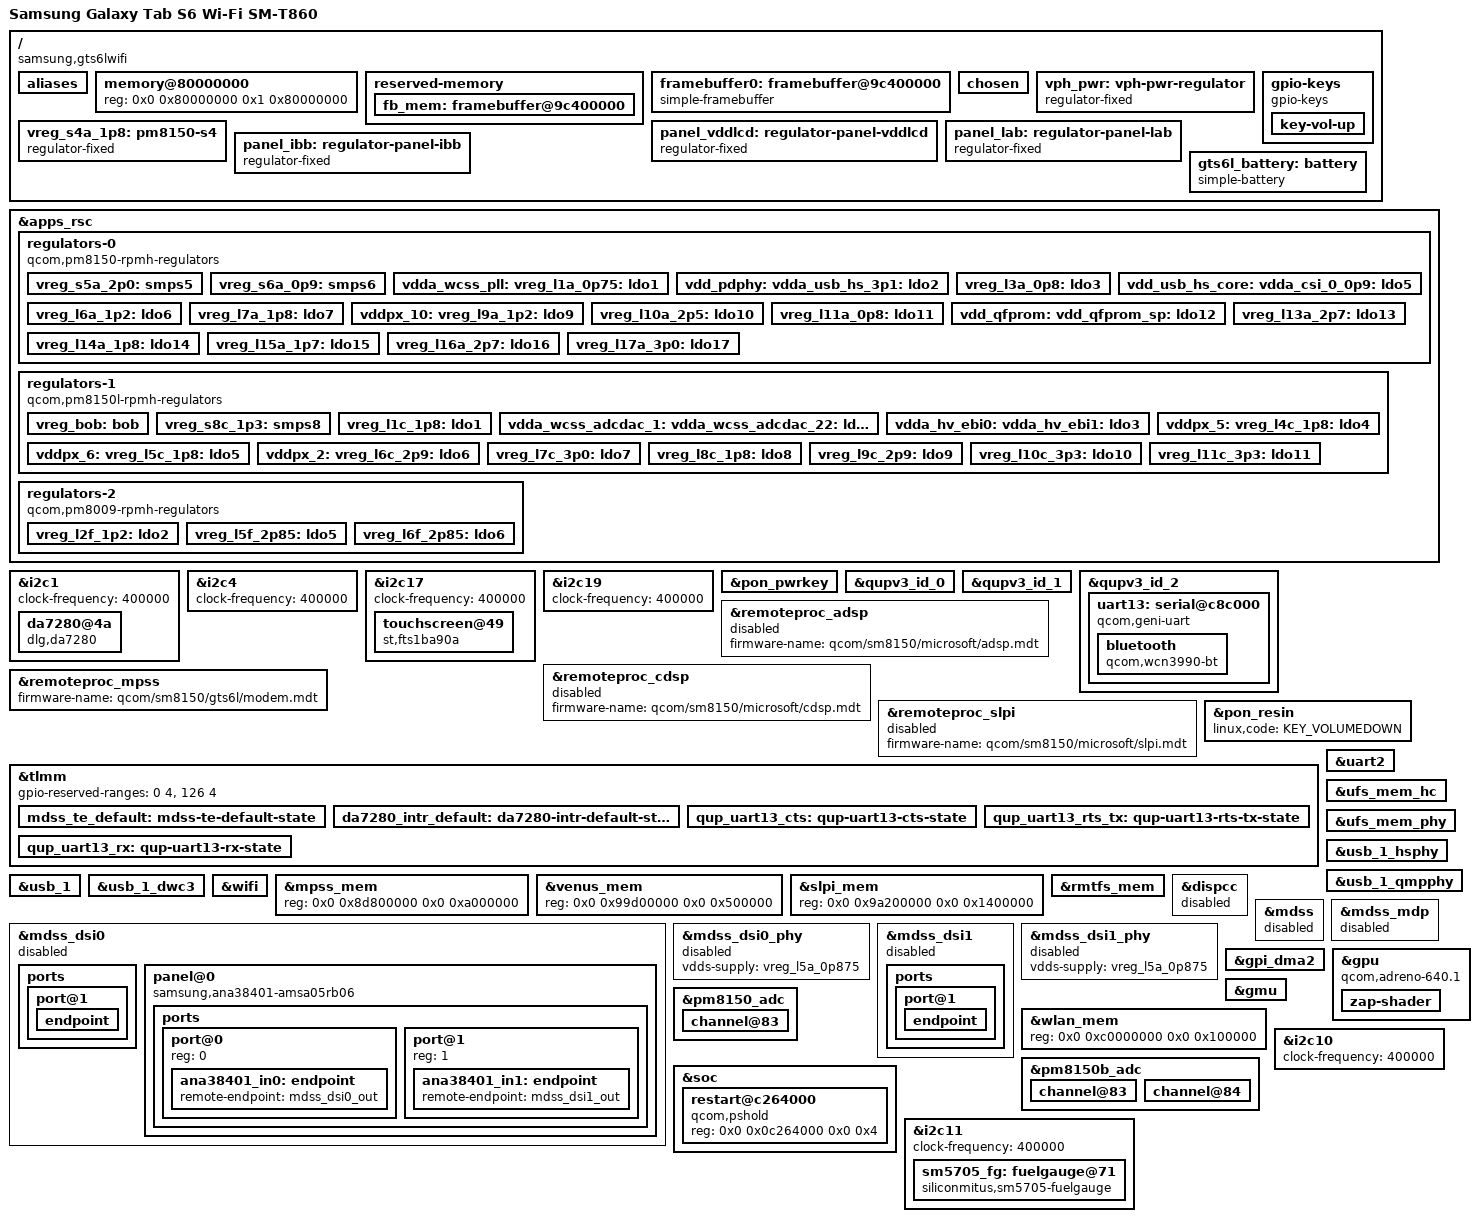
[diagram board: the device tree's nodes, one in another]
// SPDX-License-Identifier: BSD-3-Clause
/*
 * Copyright (C) 2021, Microsoft Corporation
 */

/dts-v1/;

#include <dt-bindings/regulator/qcom,rpmh-regulator.h>
#include <dt-bindings/gpio/gpio.h>
#include "sm8150.dtsi"
#include "pm8150.dtsi"
#include "pm8150b.dtsi"
#include "pm8150l.dtsi"

/ {
	model = "Samsung Galaxy Tab S6 Wi-Fi SM-T860";
	compatible = "samsung,gts6lwifi", "qcom,sm8150p", "qcom,sm8150";
	chassis-type = "tablet";

	aliases {
		serial0 = &uart2;
		/*
		 * qcom_geni_serial takes its port index from an alias, trying
		 * "serial" then "hsuart". With neither present of_alias_get_id
		 * returns -ENODEV and the probe dies with the shruggingly
		 * unhelpful "Invalid line -19". Downstream calls this same node
		 * hsuart0; serial1 is the mainline spelling and the non-console
		 * driver has its own 3-entry port array, so it does not collide
		 * with serial0 above.
		 */
		serial1 = &uart13;
	};

	memory@80000000 {
		device_type = "memory";
		reg = <0x0 0x80000000 0x1 0x80000000>;
	};

	reserved-memory {
		#address-cells = <2>;
		#size-cells = <2>;
		ranges;

		fb_mem: framebuffer@9c400000 {
			reg = <0x0 0x9c400000 0x0 0x02000000>;
			no-map;
		};
	};

	framebuffer0: framebuffer@9c400000 {
		compatible = "simple-framebuffer";
		reg = <0x0 0x9c400000 0x0 (2560 * 1600 * 4)>;
		width = <2560>;
		height = <1600>;
		stride = <(2560 * 4)>;
		format = "a8r8g8b8";
	};

	chosen {
		bootargs = "console=tty0 ignore_loglevel loglevel=8 rootwait";
	};

	vph_pwr: vph-pwr-regulator {
		compatible = "regulator-fixed";
		regulator-name = "vph_pwr";
		regulator-min-microvolt = <3700000>;
		regulator-max-microvolt = <3700000>;
	};

	/*
	 * Apparently RPMh does not provide support for PM8150 S4 because it
	 * is always-on; model it as a fixed regulator.
	 */
	vreg_s4a_1p8: pm8150-s4 {
		compatible = "regulator-fixed";
		regulator-name = "vreg_s4a_1p8";

		regulator-min-microvolt = <1800000>;
		regulator-max-microvolt = <1800000>;

		regulator-always-on;
		regulator-boot-on;

		vin-supply = <&vph_pwr>;
	};

	gpio-keys {
		compatible = "gpio-keys";

		key-vol-up {
			label = "Volume Up";
			gpios = <&pm8150_gpios 6 GPIO_ACTIVE_LOW>;
			linux,code = <KEY_VOLUMEUP>;
		};
	};
};

&apps_rsc {
	regulators-0 {
		compatible = "qcom,pm8150-rpmh-regulators";
		qcom,pmic-id = "a";

		vdd-s1-supply = <&vph_pwr>;
		vdd-s2-supply = <&vph_pwr>;
		vdd-s3-supply = <&vph_pwr>;
		vdd-s4-supply = <&vph_pwr>;
		vdd-s5-supply = <&vph_pwr>;
		vdd-s6-supply = <&vph_pwr>;
		vdd-s7-supply = <&vph_pwr>;
		vdd-s8-supply = <&vph_pwr>;
		vdd-s9-supply = <&vph_pwr>;
		vdd-s10-supply = <&vph_pwr>;

		vdd-l1-l8-l11-supply = <&vreg_s6a_0p9>;
		vdd-l2-l10-supply = <&vreg_bob>;
		vdd-l3-l4-l5-l18-supply = <&vreg_s6a_0p9>;
		vdd-l6-l9-supply = <&vreg_s8c_1p3>;
		vdd-l7-l12-l14-l15-supply = <&vreg_s5a_2p0>;
		vdd-l13-l16-l17-supply = <&vreg_bob>;

		vreg_s5a_2p0: smps5 {
			regulator-min-microvolt = <1904000>;
			regulator-max-microvolt = <2000000>;
		};

		vreg_s6a_0p9: smps6 {
			regulator-min-microvolt = <920000>;
			regulator-max-microvolt = <1128000>;
		};

		vdda_wcss_pll:
		vreg_l1a_0p75: ldo1 {
			regulator-min-microvolt = <752000>;
			regulator-max-microvolt = <752000>;
			regulator-initial-mode = <RPMH_REGULATOR_MODE_HPM>;
		};

		vdd_pdphy:
		vdda_usb_hs_3p1:
		vreg_l2a_3p1: ldo2 {
			regulator-min-microvolt = <3072000>;
			regulator-max-microvolt = <3072000>;
			regulator-initial-mode = <RPMH_REGULATOR_MODE_HPM>;
		};

		vreg_l3a_0p8: ldo3 {
			regulator-min-microvolt = <480000>;
			regulator-max-microvolt = <932000>;
			regulator-initial-mode = <RPMH_REGULATOR_MODE_HPM>;
		};

		vdd_usb_hs_core:
		vdda_csi_0_0p9:
		vdda_csi_1_0p9:
		vdda_csi_2_0p9:
		vdda_csi_3_0p9:
		vdda_dsi_0_0p9:
		vdda_dsi_1_0p9:
		vdda_dsi_0_pll_0p9:
		vdda_dsi_1_pll_0p9:
		vdda_pcie_1ln_core:
		vdda_pcie_2ln_core:
		vdda_pll_hv_cc_ebi01:
		vdda_pll_hv_cc_ebi23:
		vdda_qrefs_0p875_5:
		vdda_sp_sensor:
		vdda_ufs_2ln_core_1:
		vdda_ufs_2ln_core_2:
		vdda_usb_ss_dp_core_1:
		vdda_usb_ss_dp_core_2:
		vdda_qlink_lv:
		vdda_qlink_lv_ck:
		vreg_l5a_0p875: ldo5 {
			regulator-min-microvolt = <880000>;
			regulator-max-microvolt = <880000>;
			regulator-initial-mode = <RPMH_REGULATOR_MODE_HPM>;
		};

		vreg_l6a_1p2: ldo6 {
			regulator-min-microvolt = <1200000>;
			regulator-max-microvolt = <1200000>;
			regulator-initial-mode = <RPMH_REGULATOR_MODE_HPM>;
		};

		vreg_l7a_1p8: ldo7 {
			regulator-min-microvolt = <1800000>;
			regulator-max-microvolt = <1800000>;
			regulator-initial-mode = <RPMH_REGULATOR_MODE_HPM>;
		};

		vddpx_10:
		vreg_l9a_1p2: ldo9 {
			regulator-min-microvolt = <1200000>;
			regulator-max-microvolt = <1200000>;
			regulator-initial-mode = <RPMH_REGULATOR_MODE_HPM>;
		};

		vreg_l10a_2p5: ldo10 {
			regulator-min-microvolt = <2504000>;
			regulator-max-microvolt = <2960000>;
			regulator-initial-mode = <RPMH_REGULATOR_MODE_HPM>;
		};

		vreg_l11a_0p8: ldo11 {
			regulator-min-microvolt = <800000>;
			regulator-max-microvolt = <800000>;
			regulator-initial-mode = <RPMH_REGULATOR_MODE_HPM>;
		};

		vdd_qfprom:
		vdd_qfprom_sp:
		vdda_apc_cs_1p8:
		vdda_gfx_cs_1p8:
		vdda_usb_hs_1p8:
		vdda_qrefs_vref_1p8:
		vddpx_10_a:
		vreg_l12a_1p8: ldo12 {
			regulator-min-microvolt = <1800000>;
			regulator-max-microvolt = <1800000>;
			regulator-initial-mode = <RPMH_REGULATOR_MODE_HPM>;
		};

		vreg_l13a_2p7: ldo13 {
			regulator-min-microvolt = <2704000>;
			regulator-max-microvolt = <2704000>;
			regulator-initial-mode = <RPMH_REGULATOR_MODE_HPM>;
		};

		vreg_l14a_1p8: ldo14 {
			regulator-min-microvolt = <1800000>;
			regulator-max-microvolt = <1880000>;
			regulator-always-on;
			regulator-boot-on;
			regulator-initial-mode = <RPMH_REGULATOR_MODE_HPM>;
		};

		vreg_l15a_1p7: ldo15 {
			regulator-min-microvolt = <1704000>;
			regulator-max-microvolt = <1704000>;
			regulator-initial-mode = <RPMH_REGULATOR_MODE_HPM>;
		};

		vreg_l16a_2p7: ldo16 {
			regulator-min-microvolt = <2704000>;
			regulator-max-microvolt = <2960000>;
			regulator-initial-mode = <RPMH_REGULATOR_MODE_HPM>;
		};

		vreg_l17a_3p0: ldo17 {
			regulator-min-microvolt = <2856000>;
			regulator-max-microvolt = <3008000>;
			regulator-always-on;
			regulator-boot-on;
			regulator-initial-mode = <RPMH_REGULATOR_MODE_HPM>;
		};
	};

	regulators-1 {
		compatible = "qcom,pm8150l-rpmh-regulators";
		qcom,pmic-id = "c";

		vdd-s1-supply = <&vph_pwr>;
		vdd-s2-supply = <&vph_pwr>;
		vdd-s3-supply = <&vph_pwr>;
		vdd-s4-supply = <&vph_pwr>;
		vdd-s5-supply = <&vph_pwr>;
		vdd-s6-supply = <&vph_pwr>;
		vdd-s7-supply = <&vph_pwr>;
		vdd-s8-supply = <&vph_pwr>;

		vdd-l1-l8-supply = <&vreg_s4a_1p8>;
		vdd-l2-l3-supply = <&vreg_s8c_1p3>;
		vdd-l4-l5-l6-supply = <&vreg_bob>;
		vdd-l7-l11-supply = <&vreg_bob>;
		vdd-l9-l10-supply = <&vreg_bob>;

		vdd-bob-supply = <&vph_pwr>;
		vdd-flash-supply = <&vreg_bob>;
		vdd-rgb-supply = <&vreg_bob>;

		vreg_bob: bob {
			regulator-min-microvolt = <3008000>;
			regulator-max-microvolt = <4000000>;
			regulator-initial-mode = <RPMH_REGULATOR_MODE_AUTO>;
			regulator-allow-bypass;
		};

		vreg_s8c_1p3: smps8 {
			regulator-min-microvolt = <1352000>;
			regulator-max-microvolt = <1352000>;
		};

		vreg_l1c_1p8: ldo1 {
			regulator-min-microvolt = <1800000>;
			regulator-max-microvolt = <1800000>;
			regulator-initial-mode = <RPMH_REGULATOR_MODE_HPM>;
		};

		vdda_wcss_adcdac_1:
		vdda_wcss_adcdac_22:
		vreg_l2c_1p3: ldo2 {
			regulator-min-microvolt = <1304000>;
			regulator-max-microvolt = <1304000>;
			regulator-initial-mode = <RPMH_REGULATOR_MODE_HPM>;
			regulator-always-on;
			regulator-boot-on;
		};

		vdda_hv_ebi0:
		vdda_hv_ebi1:
		vdda_hv_ebi2:
		vdda_hv_ebi3:
		vdda_hv_refgen0:
		vdda_qlink_hv_ck:
		vreg_l3c_1p2: ldo3 {
			regulator-min-microvolt = <1200000>;
			regulator-max-microvolt = <1200000>;
			regulator-initial-mode = <RPMH_REGULATOR_MODE_HPM>;
		};

		vddpx_5:
		vreg_l4c_1p8: ldo4 {
			regulator-min-microvolt = <1704000>;
			regulator-max-microvolt = <2928000>;
			regulator-initial-mode = <RPMH_REGULATOR_MODE_HPM>;
		};

		vddpx_6:
		vreg_l5c_1p8: ldo5 {
			regulator-min-microvolt = <1704000>;
			regulator-max-microvolt = <2928000>;
			regulator-initial-mode = <RPMH_REGULATOR_MODE_HPM>;
		};

		vddpx_2:
		vreg_l6c_2p9: ldo6 {
			regulator-min-microvolt = <1800000>;
			regulator-max-microvolt = <2960000>;
			regulator-initial-mode = <RPMH_REGULATOR_MODE_HPM>;
		};

		vreg_l7c_3p0: ldo7 {
			regulator-min-microvolt = <2856000>;
			regulator-max-microvolt = <3104000>;
			regulator-initial-mode = <RPMH_REGULATOR_MODE_HPM>;
		};

		vreg_l8c_1p8: ldo8 {
			regulator-min-microvolt = <1800000>;
			regulator-max-microvolt = <1800000>;
			regulator-initial-mode = <RPMH_REGULATOR_MODE_HPM>;
		};

		vreg_l9c_2p9: ldo9 {
			regulator-min-microvolt = <2704000>;
			regulator-max-microvolt = <2960000>;
			regulator-initial-mode = <RPMH_REGULATOR_MODE_HPM>;
		};

		vreg_l10c_3p3: ldo10 {
			regulator-min-microvolt = <3000000>;
			regulator-max-microvolt = <3312000>;
			regulator-initial-mode = <RPMH_REGULATOR_MODE_HPM>;
		};

		vreg_l11c_3p3: ldo11 {
			regulator-min-microvolt = <3312000>;
			regulator-max-microvolt = <3312000>;
			regulator-initial-mode = <RPMH_REGULATOR_MODE_HPM>;
			regulator-always-on;
			regulator-boot-on;
		};
	};

	regulators-2 {
		compatible = "qcom,pm8009-rpmh-regulators";
		qcom,pmic-id = "f";

		vdd-s1-supply = <&vph_pwr>;
		vdd-s2-supply = <&vreg_bob>;

		vdd-l2-supply = <&vreg_s8c_1p3>;
		vdd-l5-l6-supply = <&vreg_bob>;

		vreg_l2f_1p2: ldo2 {
			regulator-min-microvolt = <1200000>;
			regulator-max-microvolt = <1200000>;
			regulator-initial-mode = <RPMH_REGULATOR_MODE_HPM>;
		};

		vreg_l5f_2p85: ldo5 {
			regulator-min-microvolt = <2800000>;
			regulator-max-microvolt = <2800000>;
			regulator-initial-mode = <RPMH_REGULATOR_MODE_HPM>;
		};

		vreg_l6f_2p85: ldo6 {
			regulator-initial-mode = <RPMH_REGULATOR_MODE_HPM>;
			regulator-min-microvolt = <2856000>;
			regulator-max-microvolt = <2856000>;
		};
	};
};

&i2c1 {
	status = "okay";
	clock-frequency = <400000>;


	da7280@4a {
		compatible = "dlg,da7280";
		reg = <0x4a>;
		interrupts-extended = <&tlmm 42 IRQ_TYPE_LEVEL_LOW>;
		pinctrl-names = "da7280_default";
		pinctrl-0 = <&da7280_intr_default>;

		dlg,actuator-type = "LRA";
		dlg,dlg,const-op-mode = <1>;
		dlg,dlg,periodic-op-mode = <1>;
		dlg,nom-microvolt = <2000000>;
		dlg,abs-max-microvolt = <2000000>;
		dlg,imax-microamp = <129000>;
		dlg,resonant-freq-hz = <180>;
		dlg,impd-micro-ohms = <14300000>;
		dlg,freq-track-enable;
		dlg,bemf-sens-enable;
		dlg,mem-array = <
		  0x06 0x08 0x10 0x11 0x12 0x13 0x14 0x15 0x1c 0x2a
		  0x33 0x3c 0x42 0x4b 0x4c 0x4e 0x17 0x19 0x27 0x29
		  0x17 0x19 0x03 0x84 0x5e 0x04 0x08 0x84 0x5d 0x01
		  0x84 0x5e 0x02 0x00 0xa4 0x5d 0x03 0x84 0x5e 0x06
		  0x08 0x84 0x5d 0x05 0x84 0x5d 0x06 0x84 0x5e 0x08
		  0x84 0x5e 0x05 0x8c 0x5e 0x24 0x84 0x5f 0x10 0x84
		  0x5e 0x05 0x84 0x5e 0x08 0x84 0x5f 0x01 0x8c 0x5e
		  0x04 0x84 0x5e 0x08 0x84 0x5f 0x11 0x19 0x88 0x00
		  0x00 0x00 0x00 0x00 0x00 0x00 0x00 0x00 0x00 0x00
		  0x00 0x00 0x00 0x00 0x00 0x00 0x00 0x00 0x00 0x00
		>;
	};

	/* SMB1381 @ 0x44 */
	/* MAX34417 @ 0x1c */
};

&i2c4 {
	status = "okay";
	clock-frequency = <400000>;

	/* SMB1355 @ 0x0c */
	/* SMB1390 @ 0x10 */
};

&i2c17 {
	status = "okay";
	clock-frequency = <400000>;

};

&i2c19 {
	status = "okay";
	clock-frequency = <400000>;

	/* MAX34417 @ 0x12 */
	/* MAX34417 @ 0x1a */
	/* MAX34417 @ 0x1e */
};

&pon_pwrkey {
	status = "okay";
};

&qupv3_id_0 {
	status = "okay";
};

&qupv3_id_1 {
	status = "okay";
};

&qupv3_id_2 {
	status = "okay";
};

&remoteproc_adsp {
	status = "okay";
	firmware-name = "qcom/sm8150/microsoft/adsp.mdt";
};

&remoteproc_cdsp {
	status = "okay";
	firmware-name = "qcom/sm8150/microsoft/cdsp.mdt";
};

&remoteproc_mpss {
	status = "okay";
	firmware-name = "qcom/sm8150/gts6l/modem.mdt";
};

&remoteproc_slpi {
	status = "okay";
	firmware-name = "qcom/sm8150/microsoft/slpi.mdt";
};

&pon_resin {
	status = "okay";

	linux,code = <KEY_VOLUMEDOWN>;
};

&tlmm {
	gpio-reserved-ranges = <0 4>, <126 4>;

	mdss_te_default: mdss-te-default-state {
		pins = "gpio8";
		function = "mdp_vsync";
		drive-strength = <2>;
		bias-pull-down;
	};

	da7280_intr_default: da7280-intr-default-state {
		pins = "gpio42";
		function = "gpio";
		bias-pull-up;
	};
};

&uart2 {
	status = "okay";
};

&ufs_mem_hc {
	status = "okay";

	reset-gpios = <&tlmm 175 GPIO_ACTIVE_LOW>;

	vcc-supply = <&vreg_l10a_2p5>;
	vcc-max-microamp = <750000>;
	vccq-supply = <&vreg_l9a_1p2>;
	vccq-max-microamp = <700000>;
	vccq2-supply = <&vreg_s4a_1p8>;
	vccq2-max-microamp = <750000>;
};

&ufs_mem_phy {
	status = "okay";

	vdda-phy-supply = <&vdda_ufs_2ln_core_1>;
	vdda-pll-supply = <&vreg_l3c_1p2>;
};

&usb_1_hsphy {
	status = "okay";
	vdda-pll-supply = <&vdd_usb_hs_core>;
	vdda33-supply = <&vdda_usb_hs_3p1>;
	vdda18-supply = <&vdda_usb_hs_1p8>;
};

&usb_1_qmpphy {
	status = "okay";
	vdda-phy-supply = <&vreg_l3c_1p2>;
	vdda-pll-supply = <&vdda_usb_ss_dp_core_1>;
};

&usb_1 {
	status = "okay";
};

&usb_1_dwc3 {
	dr_mode = "peripheral";
};

&wifi {
	status = "okay";

	/* Samsung truth (downstream icnss node): l1a/l7a/l2c/l11c - same set
	 * as the sm8150 HDK reference. The old vdda_wcss_* were Duo leftovers. */
	vdd-0.8-cx-mx-supply = <&vreg_l1a_0p75>;
	vdd-1.8-xo-supply = <&vreg_l7a_1p8>;
	vdd-1.3-rfa-supply = <&vreg_l2c_1p3>;
	vdd-3.3-ch0-supply = <&vreg_l11c_3p3>;
};

&remoteproc_adsp { status = "disabled"; };
&remoteproc_cdsp { status = "disabled"; };
/* mpss ENABLED for wifi: WCN3990 wlan fw runs on the modem Q6 */

/* 2023 Samsung modem image needs 160MB from 0x8d800000 (ELF phdr truth);
 * venus/slpi regions relocated out of its way - their devices are disabled,
 * the reservations just must not collide with anything. */
&mpss_mem { reg = <0x0 0x8d800000 0x0 0xa000000>; };
&venus_mem { reg = <0x0 0x99d00000 0x0 0x500000>; };
&slpi_mem { reg = <0x0 0x9a200000 0x0 0x1400000>; };

/* Samsung TZ rejects the rmtfs assign-to-MSS scm call (-22) and Samsung's
 * own dt does no vmid assign on this region - drop it so the device probes
 * and the rmtfs daemon can serve the modem's EFS. */
&rmtfs_mem {
	/delete-property/ reg;
	size = <0x0 0x400000>;
	alignment = <0x0 0x200000>;
	alloc-ranges = <0x0 0xb0000000 0x0 0x40000000>;
	qcom,use-guard-pages;
};
&remoteproc_slpi { status = "disabled"; };




&dispcc { status = "disabled"; };


/* AMOLED bias rails (lab/ibb) left enabled by the bootloader -> fixed always-on,
 * avoids needing the SPMI PMIC just to light the panel. */
/ {
	panel_vddlcd: regulator-panel-vddlcd {
		compatible = "regulator-fixed";
		regulator-name = "octa_vdd";
		regulator-min-microvolt = <3300000>;
		regulator-max-microvolt = <3300000>;
		gpio = <&tlmm 113 GPIO_ACTIVE_HIGH>;
		enable-active-high;
		regulator-boot-on;
		regulator-always-on;
	};

	panel_lab: regulator-panel-lab {
		compatible = "regulator-fixed";
		regulator-name = "panel_lab";
		regulator-min-microvolt = <6000000>;
		regulator-max-microvolt = <6000000>;
		regulator-always-on;
		regulator-boot-on;
	};

	panel_ibb: regulator-panel-ibb {
		compatible = "regulator-fixed";
		regulator-name = "panel_ibb";
		regulator-min-microvolt = <6000000>;
		regulator-max-microvolt = <6000000>;
		regulator-always-on;
		regulator-boot-on;
	};
};

&mdss {
	status = "disabled";
};

&mdss_mdp {
	status = "disabled";
};

/* dsi0 = master link */
&mdss_dsi0 {
	status = "disabled";
	vdda-supply = <&vreg_l3c_1p2>;

	qcom,dual-dsi-mode;
	qcom,master-dsi;

	pinctrl-names = "default";
	pinctrl-0 = <&mdss_te_default>;

	ports {
		port@1 {
			endpoint {
				remote-endpoint = <&ana38401_in0>;
				data-lanes = <0 1 2 3>;
				/* self-generated vsync: prove the pipe without panel TE */
				qcom,te-source = "timer0";
			};
		};
	};

	panel@0 {
		compatible = "samsung,ana38401-amsa05rb06";
		reg = <0>;

		vddio-supply = <&panel_vddlcd>;
		lab-supply = <&panel_lab>;
		ibb-supply = <&panel_ibb>;

		reset-gpios = <&tlmm 59 GPIO_ACTIVE_LOW>;
		tcon-rdy-gpios = <&tlmm 140 GPIO_ACTIVE_HIGH>;

		ports {
			#address-cells = <1>;
			#size-cells = <0>;

			port@0 {
				reg = <0>;
				ana38401_in0: endpoint {
					remote-endpoint = <&mdss_dsi0_out>;
				};
			};

			port@1 {
				reg = <1>;
				ana38401_in1: endpoint {
					remote-endpoint = <&mdss_dsi1_out>;
				};
			};
		};
	};
};

&mdss_dsi0_phy {
	status = "disabled";
	vdds-supply = <&vreg_l5a_0p875>;
};

/* dsi1 = slave link (uses dsi0 PHY PLL) */
&mdss_dsi1 {
	status = "disabled";
	vdda-supply = <&vreg_l3c_1p2>;

	qcom,dual-dsi-mode;

	assigned-clock-parents = <&mdss_dsi0_phy 0>, <&mdss_dsi0_phy 1>;

	ports {
		port@1 {
			endpoint {
				remote-endpoint = <&ana38401_in1>;
				data-lanes = <0 1 2 3>;
			};
		};
	};
};

&mdss_dsi1_phy {
	status = "disabled";
	vdds-supply = <&vreg_l5a_0p875>;
};

/* STM FingerTipS touchscreen (downstream: fts1ba90a on qupv3_se17, irq gpio 87,
 * dvdd=pm8150_l14 avdd=pm8150_l17, coords 1600x2560 portrait) */
&i2c17 {
	status = "okay";

	touchscreen@49 {
		compatible = "st,fts1ba90a";
		reg = <0x49>;
		interrupt-parent = <&tlmm>;
		interrupts = <87 IRQ_TYPE_LEVEL_LOW>;
		avdd-supply = <&vreg_l17a_3p0>;
		vdd-supply = <&vreg_l14a_1p8>;
		touchscreen-size-x = <1600>;
		touchscreen-size-y = <2560>;
		touchscreen-swapped-x-y;
		touchscreen-inverted-x;
	};
};

/* QUP2 GPI DMA engine - SE17 (touch i2c) is GSI-only per boot fw */
&gpi_dma2 { status = "okay"; };

/* Adreno 640 render-only GPU (scanout stays on simpledrm; Mesa kmsro pairs
 * them - same topology as the z3s daily driver). Zap shader is Samsung's own
 * signed a640_zap.mdt lifted from the apnhlos partition (sda16:/image/) -
 * Samsung TZ rejects the Qualcomm test-signed one in linux-firmware.
 * Speed-bin fuse cell dropped: CONFIG_QCOM_QFPROM isn't enabled and poking a
 * new TZ-guarded fuse region is needless risk; -ENOENT = all OPPs allowed. */
&gpu {
	status = "okay";
	/* Opt into the headless (render-only) msm master - scanout is simpledrm,
	 * there is no mdss node to act as the drm master otherwise. Remove this
	 * (and the adreno_device.c gate) once native display/DPU comes up. */
	compatible = "qcom,adreno-640.1", "qcom,adreno", "qcom,kgsl-3d0";
	/delete-property/ nvmem-cells;
	/delete-property/ nvmem-cell-names;

	zap-shader {
		memory-region = <&gpu_mem>;
		firmware-name = "qcom/sm8150/gts6l/a640_zap.mdt";
	};
};

&gmu {
	status = "okay";
};

/* Put the WLAN MSA in ordinary DDR that HLOS owns, at a fixed physical address.
 * Samsung's pil_wlan_fw_region (0x8bc00000) belongs to the firmware loader, so
 * qcom_scm_assign_mem() could never grant permissions on it (-22). Plain system
 * RAM is HLOS-owned, so the assign succeeds -- while still being a real physical
 * address the modem-side firmware can accept, which a self-allocated IOVA is not
 * once the SMMU is attached. */
&wlan_mem {
	reg = <0x0 0xc0000000 0x0 0x100000>;
};

/* Battery sensing. The pm8150b ADC block upstream declares only reference and
 * temperature channels, so there is no way to read the battery at all. pm8150b
 * is the PMIC carrying the charger and fuel gauge on this board.
 *
 * VBAT_SNS and VPH_PWR both arrive through a divide-by-three network, hence the
 * 1:3 pre-scaling; without it the driver reports a third of the real voltage.
 * VPH_PWR is the system rail and tracks the battery closely, so it is a useful
 * cross-check that VBAT_SNS is reading something real rather than noise. */
&pm8150b_adc {
	channel@83 {
		reg = <ADC5_VPH_PWR>;
		qcom,pre-scaling = <1 3>;
		label = "vph_pwr";
	};

	channel@84 {
		reg = <ADC5_VBAT_SNS>;
		qcom,pre-scaling = <1 3>;
		label = "vbat_sns";
	};
};

/* The battery rail, read from the PMIC that actually probes.
 *
 * VBAT_SNS lives on pm8150b (the charger PMIC), but the SPMI arbiter on this
 * board denies the applications EE the revision read on SID 2, so the MFD
 * driver never instantiates any pm8150b child at all. pm8150 (SID 0) probes
 * fine, and VPH_PWR is that PMIC's own supply rail -- which on a tablet is the
 * battery rail. It sags a little under load compared with a true VBAT_SNS
 * reading, but it tracks the battery and it is reachable. */
&pm8150_adc {
	channel@83 {
		reg = <ADC5_VPH_PWR>;
		qcom,pre-scaling = <1 3>;
		label = "vph_pwr";
	};
};

/ {
	/* Battery description. The percentage is derived from voltage against
	 * this open-circuit-voltage curve, because Qualcomm's own fuel gauge
	 * (QG) has no mainline driver and the gauge itself sits on pm8150b,
	 * which the SPMI arbiter will not let us talk to. A generic 4.4 V
	 * Li-ion curve; the pack is 7040 mAh. */
	gts6l_battery: battery {
		compatible = "simple-battery";
		voltage-min-design-microvolt = <3400000>;
		voltage-max-design-microvolt = <4400000>;
		charge-full-design-microamp-hours = <7040000>;
		ocv-capacity-celsius = <25>;
		ocv-capacity-table-0 = <4400000 100>, <4330000 95>, <4270000 90>,
			<4210000 85>, <4150000 80>, <4090000 75>, <4030000 70>,
			<3980000 65>, <3930000 60>, <3880000 55>, <3840000 50>,
			<3810000 45>, <3780000 40>, <3750000 35>, <3720000 30>,
			<3690000 25>, <3660000 20>, <3630000 15>, <3590000 10>,
			<3530000 5>, <3400000 0>;
	};

	/* Reads the battery rail through pm8150's ADC. */
	adc-battery {
		compatible = "adc-battery";
		io-channels = <&pm8150_adc ADC5_VPH_PWR>;
		io-channel-names = "voltage";
		monitored-battery = <&gts6l_battery>;
	};
};

/* Power off.
 *
 * Mainline sm8150.dtsi has no PS_HOLD node, so drivers/power/reset/msm-poweroff.c
 * ("qcom,pshold", driver name msm-restart) had no device to bind to and never
 * registered a power-off handler. reboot(RB_POWER_OFF) therefore did nothing,
 * and systemd fell back to a reboot - which is why choosing "Power Off" ended at
 * "systemd-shutdown: Rebooting." and then hung on that screen.
 *
 * Address taken from Samsung own device tree, which has
 * restart@c264000 { compatible = "qcom,pshold"; }. The driver only maps the
 * first reg, so the tcsr-boot-misc-detect range Samsung also lists is not needed.
 *
 * The driver registers a RESTART handler too, but at priority 128, below PSCI at
 * SYS_OFF_PRIO_FIRMWARE - so reboot, which already works, keeps going through
 * PSCI and only power-off gains a new path. */
&soc {
	restart@c264000 {
		compatible = "qcom,pshold";
		reg = <0x0 0x0c264000 0x0 0x4>;
	};
};

/* USB dual-role.
 *
 * This was pinned to "peripheral" so the RNDIS + ACM gadget could act as the
 * development lifeline when nothing else worked. Wi-Fi is reliable now, and a
 * tablet with no built-in keyboard badly wants to be able to host one, so the
 * port becomes dual-role instead.
 *
 * usb-role-switch registers a role switch under /sys/class/usb_role, so the
 * port can be flipped between device and host at runtime rather than being
 * fixed at build time - the gadget lifeline stays available when it is wanted.
 *
 * Caveat worth knowing before blaming the kernel: nothing here drives a VBUS
 * boost. The regulator that powers a downstream device lives in the SM5705,
 * which has no driver yet. A self-powered hub should enumerate; a bus-powered
 * keyboard plugged straight in may get no power. */
&usb_1_dwc3 {
	dr_mode = "otg";
	usb-role-switch;
};

/* SM5705 fuel gauge lives here.
 *
 * Samsung fits a Silicon Mitus SM5705 - combined charger, fuel gauge and MUIC -
 * rather than using the Qualcomm PMIC for the battery. Per Samsung own overlay
 * the gauge is at 0x71 on qupv3_se11_i2c, while the charger at 0x49 and the
 * MUIC at 0x25 sit on se4, which is already enabled as i2c4. */
&i2c11 {
	status = "okay";
	clock-frequency = <400000>;

	/* sm5705-fuelgauge@71 */
};

/* The real fuel gauge.
 *
 * This replaces the ADC-derived battery entirely. That one read the rail
 * voltage through pm8150 and mapped it against a textbook Li-ion curve, which
 * was the best available while pm8150b looked like the only option - but it
 * cannot see current, so it could never tell charging from discharging, and
 * charging inflates terminal voltage badly enough that it read 68 percent when
 * the real gauge said 46. */
&i2c11 {
	sm5705_fg: fuelgauge@71 {
		compatible = "siliconmitus,sm5705-fuelgauge";
		reg = <0x71>;
		monitored-battery = <&gts6l_battery>;
	};
};

/ {
	/delete-node/ adc-battery;
};

/* PTN36502 USB-C SuperSpeed redriver.
 *
 * USB-C can be plugged in either way round, so the SuperSpeed differential
 * pairs have to be muxed to whichever orientation the cable actually took.
 * Nothing here does that yet, which is why a USB 3 device negotiates only
 * high-speed and lands on the USB2 root hub. Samsung put a PTN36502 on se10
 * to do the muxing; enable the bus so it can at least be talked to. */
&i2c10 {
	status = "okay";
	clock-frequency = <400000>;
};

/*
 * The PMIC RTC counter CANNOT be set on this device. Do not add
 * allow-set-time here - it was tried, and it makes things worse.
 *
 * Without it rtc-pm8xxx takes the nvmem offset path and returns -ENODEV
 * immediately, quietly. With it the driver goes on to write the counter,
 * and the SPMI arbiter refuses the transaction outright:
 *
 *     spmi spmi-0: disallowed SPMI write to sid=0, addr=0x6046
 *
 * 0x6046 is the RTC control register and the firmware owns write access,
 * the same ownership wall that keeps pm8150b off limits. Because
 * CONFIG_RTC_SYSTOHC=y points at rtc0, the kernel retries this every 11
 * minutes forever - 602 denied writes in the first 122 seconds of the one
 * boot it was enabled for.
 *
 * Reading the RTC works, and alarms work, which is what suspend/resume
 * needs. Wall clock time comes from systemd-timesyncd instead.
 */

/*
 * Bluetooth: WCN3990 over UART.
 *
 * Same chip as the Wi-Fi side, but a completely separate transport: Wi-Fi is
 * ath10k_snoc talking to firmware on the modem DSP, while Bluetooth is a plain
 * HCI UART that mainline's hci_qca drives directly. The supplies are therefore
 * the same four rails the &wifi node already uses.
 *
 * The catch is that mainline's sm8150.dtsi describes this serial engine only as
 * i2c13 and spi13. It is one QUP SE that can be any of i2c, spi or uart, and
 * upstream simply never declared the uart personality for it. Downstream has it
 * as qup_uart@0xc8c000 "qcom,msm-geni-serial-hs" and it is the ONLY high-speed
 * UART downstream enables, which is what identifies it as the Bluetooth one.
 *
 * Pins come straight from the downstream qupv3_se13_4uart_pins group, and
 * mainline's pinctrl already has a matching qup13 function covering exactly
 * gpio43-46. BT_EN is gpio172, from downstream bt_en_active.
 */
&qupv3_id_2 {
	uart13: serial@c8c000 {
		compatible = "qcom,geni-uart";
		reg = <0 0x00c8c000 0 0x4000>;
		clock-names = "se";
		clocks = <&gcc GCC_QUPV3_WRAP2_S3_CLK>;
		interrupts = <GIC_SPI 585 IRQ_TYPE_LEVEL_HIGH>;
		pinctrl-names = "default";
		pinctrl-0 = <&qup_uart13_cts &qup_uart13_rts_tx &qup_uart13_rx>;
		status = "okay";

		bluetooth {
			compatible = "qcom,wcn3990-bt";

			/* The same rails as &wifi; this is one chip. */
			vddio-supply = <&vreg_s4a_1p8>;
			vddxo-supply = <&vreg_l7a_1p8>;
			vddrf-supply = <&vreg_l2c_1p3>;
			vddch0-supply = <&vreg_l11c_3p3>;

			/*
			 * Deliberately NO enable-gpios.
			 *
			 * A bt_en_active pinctrl state on gpio172 does exist in
			 * the base DTB, and it is tempting to wire it up here.
			 * It has zero consumers: the downstream BT node carries
			 * no gpio properties at all, and the part is powered
			 * purely by the three regulators above. Asserting an
			 * unrelated pad because a pinctrl group mentions it is
			 * how you break something that was working.
			 */

			max-speed = <3200000>;
		};
	};
};

&tlmm {
	/*
	 * These come from the states the downstream UART node actually points
	 * at (qupv3_se13_uart_pins: cts_active / rtstx_active / rx_active), not
	 * from the similarly named qupv3_se13_4uart_pins group next to it.
	 *
	 * The bias matters. Leaving these pins with no bias at all lets RX and
	 * CTS float, and the symptom is not a dead UART - it is a working one
	 * that occasionally garbles a frame. That showed up as
	 * "Frame reassembly failed (-84)" during the QCA handshake, and a
	 * corrupted version response makes hci_qca derive the wrong firmware
	 * name from it.
	 *
	 * Downstream also sets output-high on rts/tx in the active state. That
	 * is deliberately not copied: output-high on a pin muxed away from GPIO
	 * is not meaningful to pinctrl-msm, and every upstream QUP UART state
	 * omits it.
	 */
	qup_uart13_cts: qup-uart13-cts-state {
		pins = "gpio43";
		function = "qup13";
		drive-strength = <2>;
		bias-pull-up;
	};

	qup_uart13_rts_tx: qup-uart13-rts-tx-state {
		pins = "gpio44", "gpio45";
		function = "qup13";
		drive-strength = <2>;
		bias-pull-up;
	};

	qup_uart13_rx: qup-uart13-rx-state {
		pins = "gpio46";
		function = "qup13";
		drive-strength = <2>;
		bias-pull-up;
	};
};
